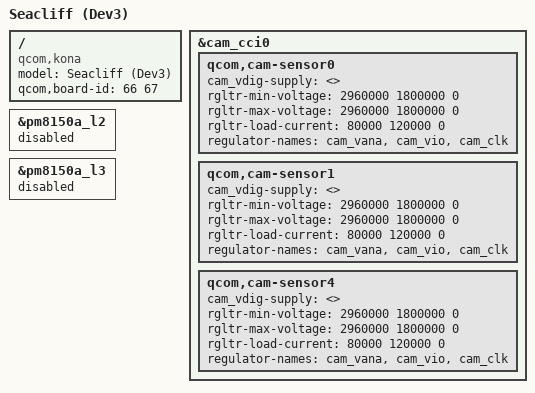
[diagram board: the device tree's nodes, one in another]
// SPDX-License-Identifier: GPL-2.0

/dts-v1/;
/plugin/;

#include "seacliff-p3.dtsi"

/ {
	model = "Seacliff (Dev3)";
	compatible = "qcom,kona";
	qcom,board-id = <66 67>;
};

&cam_cci0 {
	qcom,cam-sensor0 {
		cam_vdig-supply = <>;
		rgltr-min-voltage = <2960000 1800000 0>;
		rgltr-max-voltage = <2960000 1800000 0>;
		rgltr-load-current = <80000 120000 0>;
		regulator-names = "cam_vana", "cam_vio",
			"cam_clk";
	};

	qcom,cam-sensor1 {
		cam_vdig-supply = <>;
		rgltr-min-voltage = <2960000 1800000 0>;
		rgltr-max-voltage = <2960000 1800000 0>;
		rgltr-load-current = <80000 120000 0>;
		regulator-names = "cam_vana", "cam_vio",
			"cam_clk";
	};

	qcom,cam-sensor4 {
		cam_vdig-supply = <>;
		rgltr-min-voltage = <2960000 1800000 0>;
		rgltr-max-voltage = <2960000 1800000 0>;
		rgltr-load-current = <80000 120000 0>;
		regulator-names = "cam_vana", "cam_vio",
			"cam_clk";
	};
};

&pm8150a_l2 {
	status = "disabled";
};

&pm8150a_l3 {
	status = "disabled";
};
